# ODS5010 register map
Vendor: OCS; Series: ODS5010; File version: 1.0
CPU: CM0plus r0p0, little endian, MPU, FPU, 4 interrupt priority bits
Registers are 32-bit, read-write, reset 0x0 unless marked. A register's access mark holds for its fields unless they carry their own. Offsets are from the block's base; [hi:lo] are bit positions; {n}, {i} and the like mark numbered series.

## SPI0 — Serial Peripheral Interface (SPI0) Peripheral
Base 0x40003800; register names take the prefix SPI_0
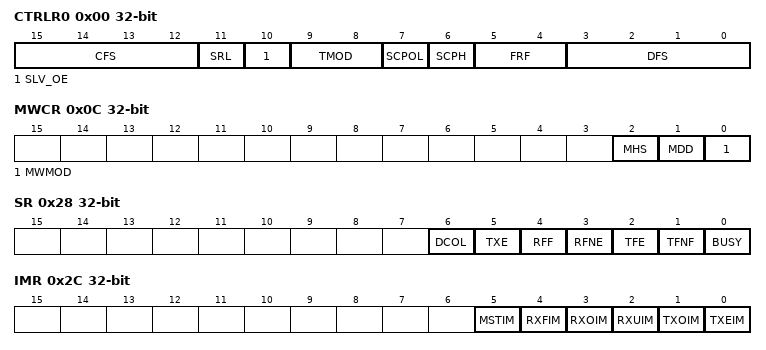
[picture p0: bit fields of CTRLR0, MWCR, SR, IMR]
0x00 CTRLR0 — Control Register 0
  [15:12] CFS — Control Frame Size
  [11] SRL — Shift Register Loop
  [10] SLV_OE — Slave Output Enable
  [9:8] TMOD — Transfer Mode
  [7] SCPOL — Serial Clock Polarity
  [6] SCPH — Serial Clock Phase
  [5:4] FRF — Frame Format
  [3:0] DFS — Data Frame Size
0x04 CTRLR1 — Control Register 1
  [15:0] NDF — Number of Data Frames
0x08 SPIENR — SPI Enable Register
  [0] SPI_EN — SPI Enable
0x0C MWCR — Microwire Control Register
  [2] MHS — Microwire Handshaking
  [1] MDD — Microwire Data Direction
  [0] MWMOD — Microwire Transfer Mode
0x10 SER — Slave Enable Register
  [15:0] SER — Slave Enable
0x14 BAUDR — Baud Rate Select Register
  [15:0] SCKDV — Clock Divider
0x18 TXFTLR — Transmit FIFO Threshold Level Register
  [7:0] TFT — Transmit FIFO Threshold
0x1C RXFTLR — Receive FIFO Threshold Level Register
  [7:0] RFT — Receive FIFO Threshold
0x20 TXFLR — Transmit FIFO Level Register
  [7:0] TXTFL — Transmit FIFO Level
0x24 RXFLR — Receive FIFO Level Register
  [7:0] RXTFL — Receive FIFO Level
0x28 SR — Status Register
  [6] DCOL — Data Collision Error
  [5] TXE — Transmission Error
  [4] RFF — Receive FIFO Full
  [3] RFNE — Receive FIFO Not Empty
  [2] TFE — Transmit FIFO Empty
  [1] TFNF — Transmit FIFO Not Full
  [0] BUSY — Busy Flag
0x2C IMR — Interrupt Mask Register
  [5] MSTIM — Multi-Master Interrupt Mask
  [4] RXFIM — RX FIFO Full Interrupt Mask
  [3] RXOIM — RX FIFO Overflow Interrupt Mask
  [2] RXUIM — RX FIFO Underflow Interrupt Mask
  [1] TXOIM — TX FIFO Overflow Interrupt Mask
  [0] TXEIM — TX FIFO Empty Interrupt Mask
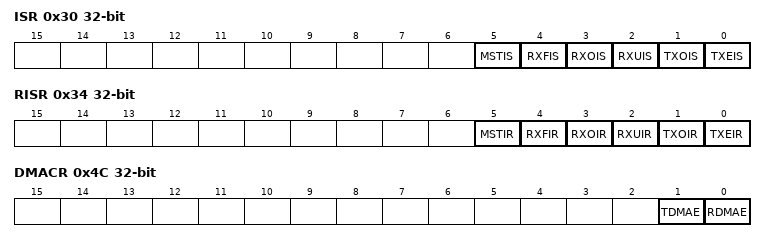
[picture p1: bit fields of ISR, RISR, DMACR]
0x30 ISR — Interrupt Status Register
  [5] MSTIS — Multi-Master Interrupt Status
  [4] RXFIS — RX FIFO Full Interrupt Status
  [3] RXOIS — RX FIFO Overflow Interrupt Status
  [2] RXUIS — RX FIFO Underflow Interrupt Status
  [1] TXOIS — TX FIFO Overflow Interrupt Status
  [0] TXEIS — TX FIFO Empty Interrupt Status
0x34 RISR — Raw Interrupt Status Register
  [5] MSTIR — Multi-Master Raw Interrupt
  [4] RXFIR — RX FIFO Full Raw Interrupt
  [3] RXOIR — RX FIFO Overflow Raw Interrupt
  [2] RXUIR — RX FIFO Underflow Raw Interrupt
  [1] TXOIR — TX FIFO Overflow Raw Interrupt
  [0] TXEIR — TX FIFO Empty Raw Interrupt
0x38 TXOICR — Transmit FIFO Overflow Interrupt Clear Register
  [0] TXOICR — Clear TX Overflow Interrupt
0x3C RXOICR — Receive FIFO Overflow Interrupt Clear Register
  [0] RXOICR — Clear RX Overflow Interrupt
0x40 RXUICR — Receive FIFO Underflow Interrupt Clear Register
  [0] RXUICR — Clear RX Underflow Interrupt
0x44 MSTICR — Multi-Master Interrupt Clear Register
  [0] MSTICR — Clear Multi-Master Interrupt
0x48 ICR — Interrupt Clear Register
  [0] ICR — Clear All Interrupts
0x4C DMACR — DMA Control Register
  [1] TDMAE — Transmit DMA Enable
  [0] RDMAE — Receive DMA Enable
0x50 DMATDLR — DMA Transmit Data Level Register
  [7:0] DMATDL — DMA Transmit Data Level
0x54 DMARDLR — DMA Receive Data Level Register
  [7:0] DMARDL — DMA Receive Data Level
0x58 IDR — Identification Register
  [31:0] ID — Peripheral ID
0x5C SPI_COMP_VERSION — Component Version Register
  [31:0] VERSION — Component Version
{0x60+4i} DR_{i} (i=0..35) — Data Register {i}
  [15:0] DATA
0xF0 RX_SAMPLE_DLY — RXD Sample Delay Register
  [7:0] RSD — RXD Sample Delay

## SPI1 — Serial Peripheral Interface (SPI1) Peripheral
Base 0x40013800; register names take the prefix SPI_1
Registers as SPI0.

## UART0 — Universal Asynchronous Receiver/Transmitter 0
Base 0x40004000; register names take the prefix UART0_
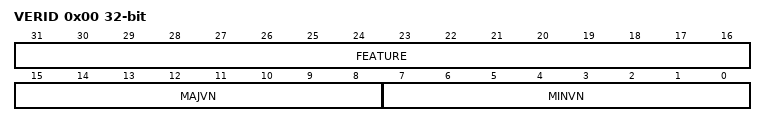
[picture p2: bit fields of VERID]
0x00 VERID ro — Version ID Register
  [31:16] FEATURE — Feature Identification
  [15:8] MAJVN — Major Version Number
  [7:0] MINVN — Minor Version Number
0x04 SR — Status Register
  [31:0] SR — Status Register Bits
0x08 IR — Interrupt Register
  [31:0] IR — Interrupt Register Bits
0x0C IER — Interrupt Enable Register
  [31:0] IER — Interrupt Enable Bits
0x10 BRR — Baud Rate Register
  [15:0] BR — Baud Rate Value
0x14 DR — Data Register
  [31:0] DR — Data Register Bits
0x18 CR — Control Register
  [31:0] CR — Control Register Bits
0x1C MATCH
  [31:0] MATCH — Match Value
0x2C WATER — Watermark Register
  [31:0] WATER — Watermark Value

## UART1 — Universal Asynchronous Receiver/Transmitter 1
Base 0x40004400; register names take the prefix UART1_
Registers as UART0.
